VERSION ""

NS_ :

BS_:

BU_: XXX 0

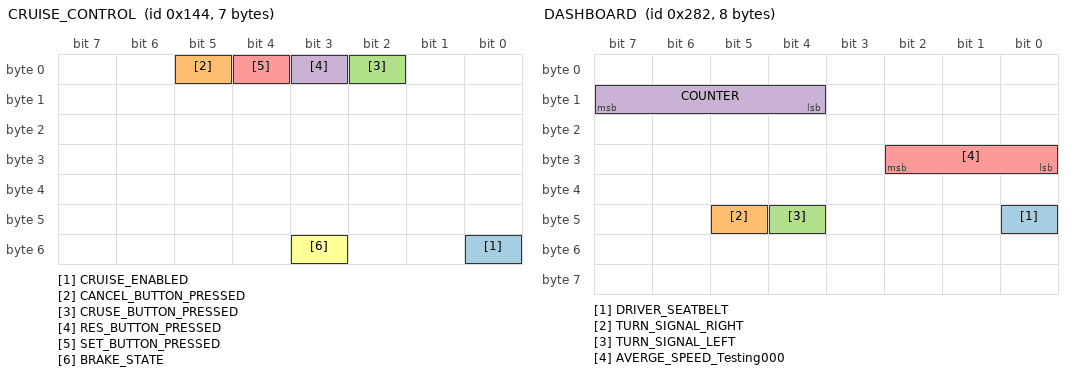
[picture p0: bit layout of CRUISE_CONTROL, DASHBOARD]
BO_ 324 CRUISE_CONTROL: 7 XXX
 SG_ CRUISE_ENABLED : 48|1@0+ (1,0) [0|0] "" XXX
 SG_ CANCEL_BUTTON_PRESSED : 5|1@0+ (1,0) [0|1] "" XXX
 SG_ CRUSE_BUTTON_PRESSED : 2|1@0+ (1,0) [0|1] "" XXX
 SG_ RES_BUTTON_PRESSED : 3|1@0+ (1,0) [0|1] "" XXX
 SG_ SET_BUTTON_PRESSED : 4|1@0+ (1,0) [0|1] "" XXX
 SG_ BRAKE_STATE : 51|1@0+ (1,0) [0|0] "" XXX

BO_ 642 DASHBOARD: 8 XXX
 SG_ DRIVER_SEATBELT : 40|1@0+ (1,0) [0|1] "" XXX
 SG_ TURN_SIGNAL_RIGHT : 45|1@0+ (1,0) [0|1] "" XXX
 SG_ TURN_SIGNAL_LEFT : 44|1@0+ (1,0) [0|1] "" XXX
 SG_ COUNTER : 12|4@1+ (1,0) [0|255] "" XXX
 SG_ AVERGE_SPEED_Testing000 : 24|3@1+ (1,0) [0|7] "" XXX

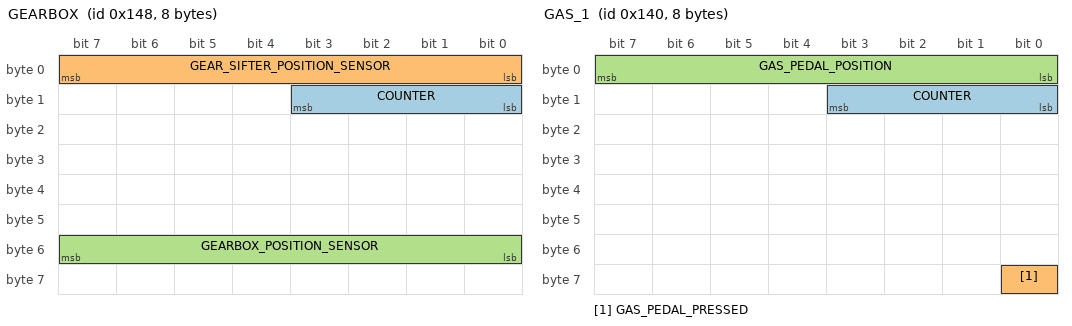
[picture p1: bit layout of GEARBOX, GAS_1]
BO_ 328 GEARBOX: 8 XXX
 SG_ COUNTER : 8|4@1+ (1,0) [0|255] "" XXX
 SG_ GEAR_SIFTER_POSITION_SENSOR : 0|8@1+ (1,0) [0|255] "" XXX
 SG_ GEARBOX_POSITION_SENSOR : 48|8@1+ (1,0) [0|255] "" XXX

BO_ 320 GAS_1: 8 XXX
 SG_ COUNTER : 8|4@1+ (1,0) [0|15] "" XXX
 SG_ GAS_PEDAL_PRESSED : 56|1@0+ (1,0) [0|1] "" XXX
 SG_ GAS_PEDAL_POSITION : 7|8@0+ (1,0) [0|255] "" XXX

BO_ 209 BRAKE_PEDAL_POSITION: 8 XXX
 SG_ BRAKE_PEDAL_POSITION : 23|8@0+ (1,0) [0|255] "" XXX

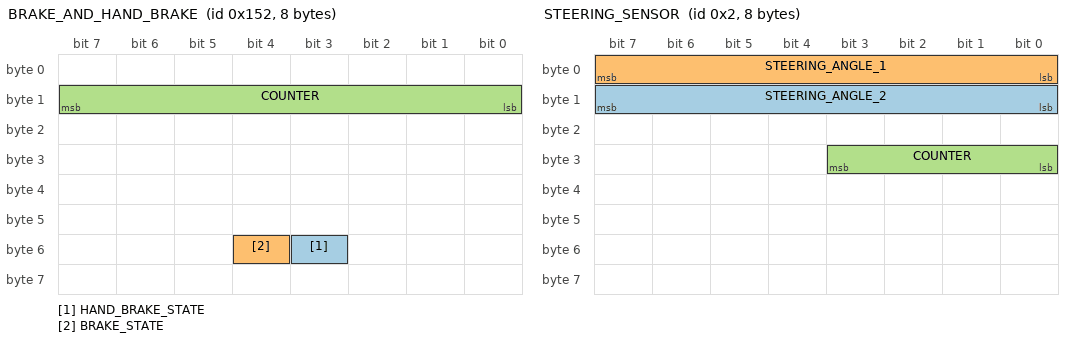
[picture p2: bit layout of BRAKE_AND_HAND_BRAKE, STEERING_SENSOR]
BO_ 338 BRAKE_AND_HAND_BRAKE: 8 XXX
 SG_ HAND_BRAKE_STATE : 51|1@0+ (1,0) [0|1] "" XXX
 SG_ BRAKE_STATE : 52|1@0+ (1,0) [0|1] "" XXX
 SG_ COUNTER : 8|8@1+ (1,0) [0|255] "" XXX

BO_ 2 STEERING_SENSOR: 8 XXX
 SG_ STEERING_ANGLE_2 : 8|8@1+ (1,0) [0|255] "" XXX
 SG_ STEERING_ANGLE_1 : 7|8@0+ (1,0) [0|1] "" XXX
 SG_ COUNTER : 24|4@1+ (1,0) [0|255] "" XXX

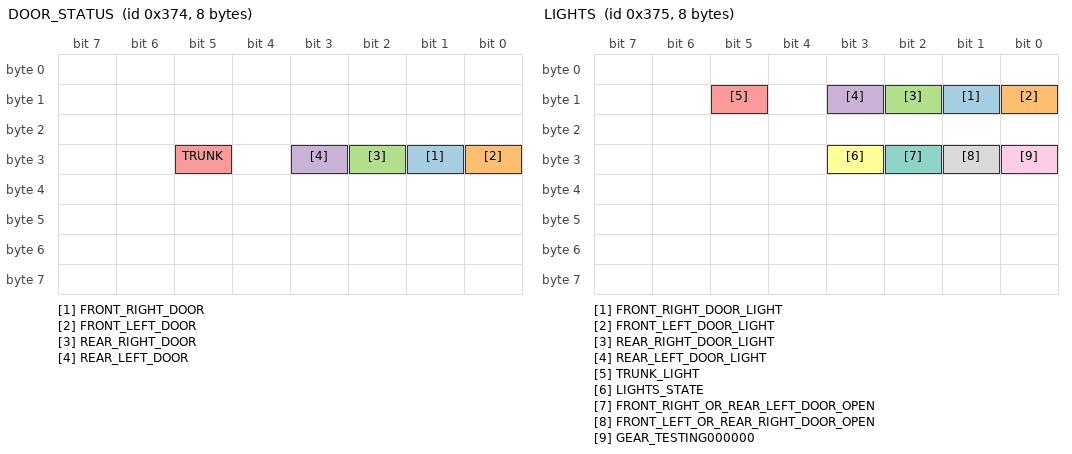
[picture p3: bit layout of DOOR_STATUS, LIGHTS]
BO_ 884 DOOR_STATUS: 8 XXX
 SG_ FRONT_RIGHT_DOOR : 25|1@0+ (1,0) [0|1] "" XXX
 SG_ FRONT_LEFT_DOOR : 24|1@0+ (1,0) [0|1] "" XXX
 SG_ REAR_RIGHT_DOOR : 26|1@0+ (1,0) [0|1] "" XXX
 SG_ REAR_LEFT_DOOR : 27|1@0+ (1,0) [0|1] "" XXX
 SG_ TRUNK : 29|1@0+ (1,0) [0|1] "" XXX

BO_ 885 LIGHTS: 8 XXX
 SG_ FRONT_RIGHT_DOOR_LIGHT : 9|1@0+ (1,0) [0|1] "" XXX
 SG_ FRONT_LEFT_DOOR_LIGHT : 8|1@0+ (1,0) [0|1] "" XXX
 SG_ REAR_RIGHT_DOOR_LIGHT : 10|1@0+ (1,0) [0|1] "" XXX
 SG_ REAR_LEFT_DOOR_LIGHT : 11|1@0+ (1,0) [0|1] "" XXX
 SG_ TRUNK_LIGHT : 13|1@0+ (1,0) [0|1] "" XXX
 SG_ LIGHTS_STATE : 27|1@0+ (1,0) [0|1] "" XXX
 SG_ FRONT_RIGHT_OR_REAR_LEFT_DOOR_OPEN : 26|1@0+ (1,0) [0|1] "" XXX
 SG_ FRONT_LEFT_OR_REAR_RIGHT_DOOR_OPEN : 25|1@0+ (1,0) [0|1] "" XXX
 SG_ GEAR_TESTING000000 : 24|1@0+ (1,0) [0|1] "" XXX

BO_ 1632 NEW_MSG_1: 8 XXX
 SG_ COUNTER : 63|8@0+ (1,0) [0|255] "" XXX

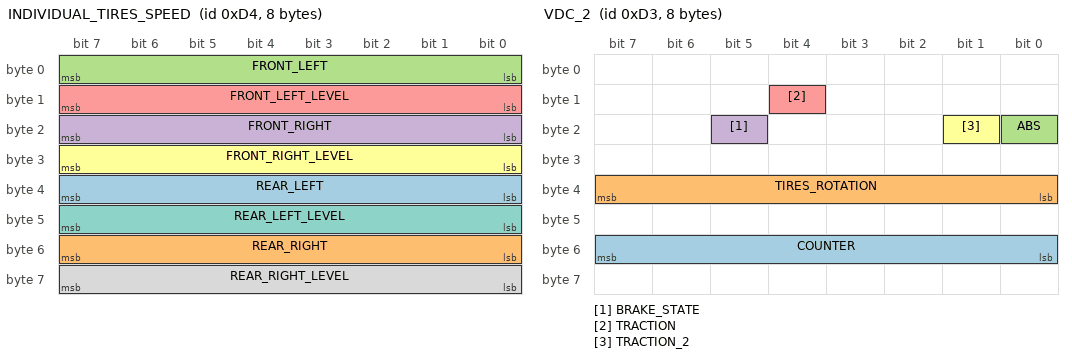
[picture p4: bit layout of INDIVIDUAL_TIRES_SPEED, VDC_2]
BO_ 212 INDIVIDUAL_TIRES_SPEED: 8 XXX
 SG_ REAR_LEFT : 32|8@1+ (1,0) [0|255] "" XXX
 SG_ REAR_RIGHT : 48|8@1+ (1,0) [0|255] "" XXX
 SG_ FRONT_LEFT : 0|8@1+ (1,0) [0|255] "" XXX
 SG_ FRONT_RIGHT : 16|8@1+ (1,0) [0|255] "" XXX
 SG_ FRONT_LEFT_LEVEL : 8|8@1+ (1,0) [0|255] "" XXX
 SG_ FRONT_RIGHT_LEVEL : 24|8@1+ (1,0) [0|255] "" XXX
 SG_ REAR_LEFT_LEVEL : 40|8@1+ (1,0) [0|255] "" XXX
 SG_ REAR_RIGHT_LEVEL : 56|8@1+ (1,0) [0|255] "" XXX

BO_ 342 FUEL_LEVEL: 8 XXX
 SG_ FUEL_LEVEL : 63|8@0+ (1,0) [0|255] "" XXX

BO_ 1786 NEW_MSG_3: 8 XXX
 SG_ COUNTER : 3|4@0+ (1,0) [0|255] "" XXX

BO_ 882 NEW_MSG_4: 8 XXX
 SG_ COUNTER : 15|4@0+ (1,0) [0|15] "" XXX

BO_ 211 VDC_2: 8 XXX
 SG_ COUNTER : 55|8@0+ (1,0) [0|255] "" XXX
 SG_ TIRES_ROTATION : 32|8@1+ (1,0) [0|255] "" XXX
 SG_ ABS : 16|1@0+ (1,0) [0|1] "" XXX
 SG_ BRAKE_STATE : 21|1@0+ (1,0) [0|1] "" XXX
 SG_ TRACTION : 12|1@0+ (1,0) [0|1] "" XXX
 SG_ TRACTION_2 : 17|1@1+ (1,0) [0|15] "" XXX

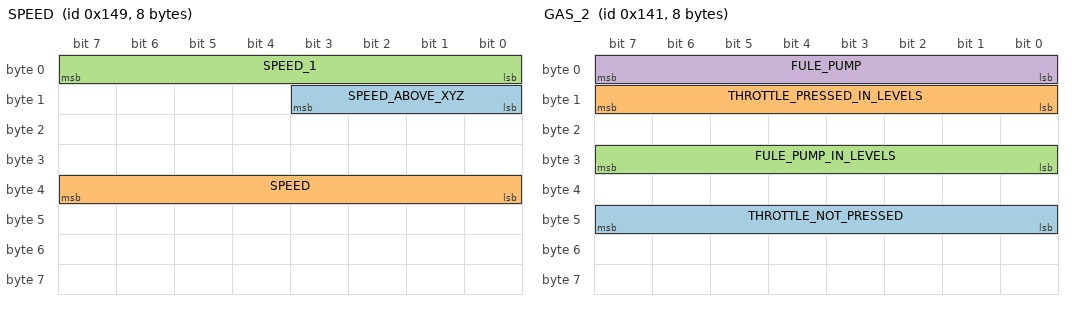
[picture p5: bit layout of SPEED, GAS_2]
BO_ 329 SPEED: 8 XXX
 SG_ SPEED_ABOVE_XYZ : 8|4@1+ (1,0) [0|255] "" XXX
 SG_ SPEED : 32|8@1+ (1,0) [0|255] "" XXX
 SG_ SPEED_1 : 0|8@1+ (1,0) [0|255] "" XXX

BO_ 321 GAS_2: 8 XXX
 SG_ THROTTLE_NOT_PRESSED : 40|8@1+ (1,0) [0|255] "" XXX
 SG_ THROTTLE_PRESSED_IN_LEVELS : 8|8@1+ (1,0) [0|255] "" XXX
 SG_ FULE_PUMP_IN_LEVELS : 24|8@1+ (1,0) [0|255] "" XXX
 SG_ FULE_PUMP : 0|8@1+ (1,0) [0|255] "" XXX

BO_ 640 NEW_MSG_6: 8 XXX
 SG_ COUNTER : 8|4@1+ (1,0) [0|15] "" XXX

BO_ 865 NEW_MSG_8: 8 XXX
 SG_ COUNTER : 32|4@1+ (1,0) [0|15] "" XXX

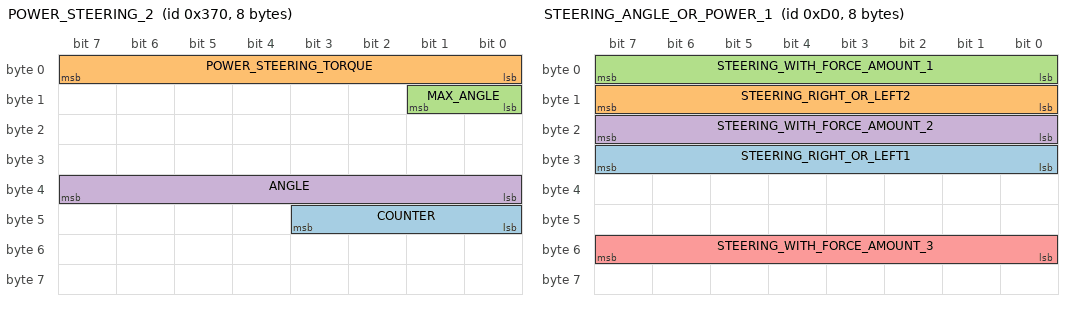
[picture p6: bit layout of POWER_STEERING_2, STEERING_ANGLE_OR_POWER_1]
BO_ 880 POWER_STEERING_2: 8 XXX
 SG_ COUNTER : 40|4@1+ (1,0) [0|255] "" XXX
 SG_ POWER_STEERING_TORQUE : 0|8@1+ (1,0) [0|7] "" XXX
 SG_ MAX_ANGLE : 8|2@1+ (1,0) [0|3] "" XXX
 SG_ ANGLE : 32|8@1+ (1,0) [0|255] "" XXX

BO_ 208 STEERING_ANGLE_OR_POWER_1: 8 XXX
 SG_ STEERING_RIGHT_OR_LEFT1 : 24|8@1+ (1,0) [0|255] "" XXX
 SG_ STEERING_RIGHT_OR_LEFT2 : 8|8@1+ (1,0) [0|255] "" XXX
 SG_ STEERING_WITH_FORCE_AMOUNT_1 : 0|8@1+ (1,0) [0|255] "" XXX
 SG_ STEERING_WITH_FORCE_AMOUNT_2 : 16|8@1+ (1,0) [0|255] "" XXX
 SG_ STEERING_WITH_FORCE_AMOUNT_3 : 48|8@1+ (1,0) [0|255] "" XXX

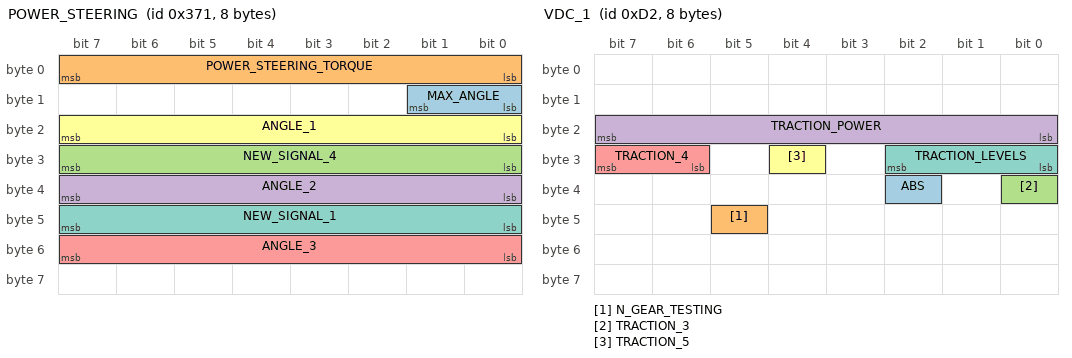
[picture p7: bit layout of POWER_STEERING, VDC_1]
BO_ 881 POWER_STEERING: 8 XXX
 SG_ MAX_ANGLE : 8|2@1+ (1,0) [0|3] "" XXX
 SG_ POWER_STEERING_TORQUE : 0|8@1+ (1,0) [0|255] "" XXX
 SG_ NEW_SIGNAL_4 : 24|8@1+ (1,0) [0|255] "" XXX
 SG_ ANGLE_2 : 32|8@1+ (1,0) [0|255] "" XXX
 SG_ ANGLE_3 : 48|8@1+ (1,0) [0|255] "" XXX
 SG_ ANGLE_1 : 16|8@1+ (1,0) [0|255] "" XXX
 SG_ NEW_SIGNAL_1 : 40|8@1+ (1,0) [0|255] "" XXX

BO_ 977 NEW_MSG_5: 8 XXX

BO_ 210 VDC_1: 8 XXX
 SG_ ABS : 34|1@0+ (1,0) [0|1] "" XXX
 SG_ N_GEAR_TESTING : 45|1@1+ (1,0) [0|255] "" XXX
 SG_ TRACTION_3 : 32|1@1+ (1,0) [0|3] "" XXX
 SG_ TRACTION_POWER : 16|8@1+ (1,0) [0|255] "" XXX
 SG_ TRACTION_4 : 31|2@0+ (1,0) [0|15] "" XXX
 SG_ TRACTION_5 : 28|1@0+ (1,0) [0|1] "" XXX
 SG_ TRACTION_LEVELS : 24|3@1+ (1,0) [0|255] "" XXX

BO_ 864 Testing_GAS_or_Fule_Pump: 8 XXX
 SG_ GAS_POSITION_Testing000 : 32|8@1+ (1,0) [0|255] "" XXX

BO_ 872 NEW_MSG_7: 8 XXX

BO_ 644 NEW_MSG_9: 8 XXX
